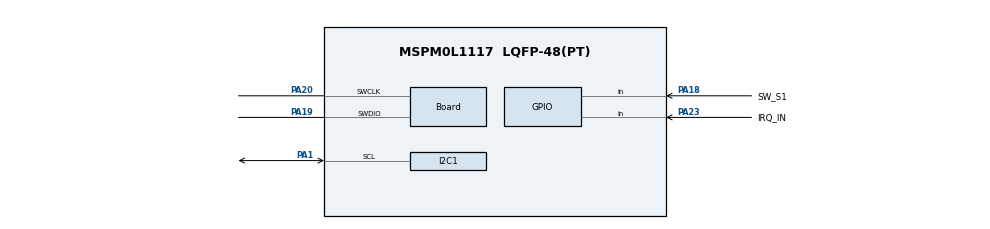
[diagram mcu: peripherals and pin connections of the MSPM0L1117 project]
//@cliArgs --device "MSPM0L111X" --package "LQFP-48(PT)" --part "Default"
//@v2CliArgs --device "MSPM0L1117" --package "LQFP-48(PT)"
// @cliArgs --board /ti/boards/LP_MSPM0L1117 --rtos nortos

/**
 * Import the modules used in this configuration.
 */
const Board  = scripting.addModule("/ti/driverlib/Board");
const GPIO   = scripting.addModule("/ti/driverlib/GPIO", {}, false);
const GPIO1  = GPIO.addInstance();
const GPIO2  = GPIO.addInstance();
const I2C    = scripting.addModule("/ti/driverlib/I2C", {}, false);
const I2C1   = I2C.addInstance();
const SYSCTL = scripting.addModule("/ti/driverlib/SYSCTL");
const TIMER  = scripting.addModule("/ti/driverlib/TIMER", {}, false);
const TIMER1 = TIMER.addInstance();
const TIMER2 = TIMER.addInstance();

/**
 * Write custom configuration values to the imported modules.
 */
Board.configureUnused             = true;
Board.genPeriphPinFile            = true;
Board.peripheral.$assign          = "DEBUGSS";
Board.peripheral.swclkPin.$assign = "PA20";
Board.peripheral.swdioPin.$assign = "PA19";
Board.genFileMod.$name            = "ti_driverlib_BoardPins0";

GPIO1.$name                              = "GPIO_A";
GPIO1.port                               = "PORTA";
GPIO1.associatedPins.create(3);
GPIO1.associatedPins[0].direction        = "INPUT";
GPIO1.associatedPins[0].internalResistor = "PULL_UP";
GPIO1.associatedPins[0].inputFilter      = "8_CYCLES";
GPIO1.associatedPins[0].interruptEn      = true;
GPIO1.associatedPins[0].assignedPort     = "PORTA";
GPIO1.associatedPins[0].polarity         = "RISE_FALL";
GPIO1.associatedPins[0].$name            = "SW_S2_USER";
GPIO1.associatedPins[0].assignedPin      = "5";
GPIO1.associatedPins[1].initialValue     = "SET";
GPIO1.associatedPins[1].subOutputPolicy  = "TOGGLE";
GPIO1.associatedPins[1].subChanID        = 1;
GPIO1.associatedPins[1].direction        = "INPUT";
GPIO1.associatedPins[1].assignedPin      = "23";
GPIO1.associatedPins[1].$name            = "IRQ_IN";
GPIO1.associatedPins[1].internalResistor = "PULL_UP";
GPIO1.associatedPins[1].assignedPort     = "PORTA";
GPIO1.associatedPins[1].inputFilter      = "3_CYCLES";
GPIO1.associatedPins[1].interruptEn      = true;
GPIO1.associatedPins[1].polarity         = "FALL";
GPIO1.associatedPins[1].pin.$assign      = "PA23";
GPIO1.associatedPins[2].direction        = "INPUT";
GPIO1.associatedPins[2].assignedPort     = "PORTA";
GPIO1.associatedPins[2].assignedPin      = "18";
GPIO1.associatedPins[2].interruptEn      = true;
GPIO1.associatedPins[2].polarity         = "RISE_FALL";
GPIO1.associatedPins[2].$name            = "SW_S1";
GPIO1.associatedPins[2].pin.$assign      = "PA18";

GPIO2.$name                         = "GPIO_B";
GPIO2.port                          = "PORTB";
GPIO2.associatedPins.create(3);
GPIO2.associatedPins[0].$name       = "LED_RGB_GREEN";
GPIO2.associatedPins[0].assignedPin = "18";
GPIO2.associatedPins[1].$name       = "LED_RGB_RED";
GPIO2.associatedPins[1].assignedPin = "17";
GPIO2.associatedPins[2].$name       = "LED_RGB_BLUE";
GPIO2.associatedPins[2].assignedPin = "16";

I2C1.basicTargetAddress                      = 0x48;
I2C1.advTargetClkStretch                     = false;
I2C1.basicEnableController                   = true;
I2C1.$name                                   = "I2C_CONTROLLER";
I2C1.intController                           = ["NACK","RXFIFO_TRIGGER","RX_DONE","START","TXFIFO_TRIGGER","TX_DONE"];
I2C1.advControllerClkStretch                 = false;
I2C1.advControllerTXFIFOTRIG                 = "BYTES_1";
I2C1.peripheral.$assign                      = "I2C0";
I2C1.peripheral.sdaPin.$assignAllowConflicts = "PA0";
I2C1.peripheral.sclPin.$assign               = "PA1";

SYSCTL.clockTreeEn = true;
SYSCTL.powerPolicy = "STANDBY1";

TIMER1.interrupts                  = ["ZERO"];
TIMER1.timerPeriod                 = "10 ms";
TIMER1.timerClkSrc                 = "LFCLK";
TIMER1.event1ControllerInterruptEn = ["ZERO_EVENT"];
TIMER1.$name                       = "TIMG_DELAY_BLOCKING";
TIMER1.peripheral.$assign          = "TIMG1";

TIMER2.timerClkPrescale            = 256;
TIMER2.interrupts                  = ["ZERO"];
TIMER2.timerPeriod                 = "10 ms";
TIMER2.timerClkSrc                 = "LFCLK";
TIMER2.event1ControllerInterruptEn = ["ZERO_EVENT"];
TIMER2.$name                       = "TIMG_DELAY_NO_BLOCKING";
TIMER2.peripheral.$assign          = "TIMG0";

const ProjectConfig              = scripting.addModule("/ti/project_config/ProjectConfig", {}, false);
ProjectConfig.migrationCondition = true;
